AUTOSAR XML (schema 4-2-2)
package /Components
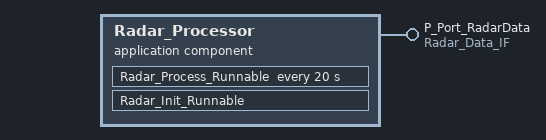
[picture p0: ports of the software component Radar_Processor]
  application sw component type Radar_Processor
    provide port P_Port_RadarData: provided-interface=Radar_Data_IF
    behavior Radar_Processor_InternalBehavior
      init event Radar_Init_Event: start-on-event=Radar_Init_Runnable
      timing event Radar_Process_Event: start-on-event=Radar_Process_Runnable, period=20
      runnable Radar_Init_Runnable
        parameter access PA_Init_Radar_Params: accessed-parameter=P_Port_RadarData.Radar_PointCloud
      runnable Radar_Process_Runnable: minimum-start-interval=20
        data-send-points:
          access VA_Send_Radar_PointCloud: accessed-variable=P_Port_RadarData.Radar_PointCloud
          access VA_Send_Radar_Tracks: accessed-variable=P_Port_RadarData.Radar_Tracks
        parameter access PA_Run_Radar_PointCloud_Params: accessed-parameter=P_Port_RadarData.Radar_PointCloud
        parameter access PA_Run_Radar_Tracks_Params: accessed-parameter=P_Port_RadarData.Radar_Tracks
